# DCC_DCC2_00800000h register map
Vendor: Texas Instruments
Peripheral module from a debugger description file (folder AM275x).
Registers are 32-bit, read-write, reset 0x0 unless marked. A register's access mark holds for its fields unless they carry their own. Offsets are as the file gives them; lines under a group give offsets from that group; [hi:lo] are bit positions; {n}, {i} and the like mark numbered series; 'fields as' and 'values as' point back to an identical list; <NAME> marks a mode.

## dcc2
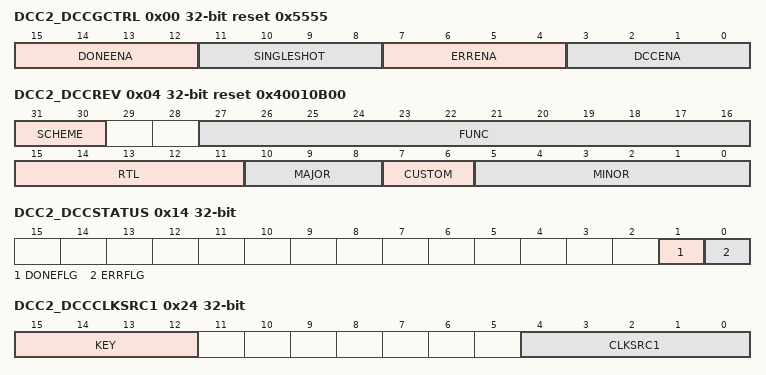
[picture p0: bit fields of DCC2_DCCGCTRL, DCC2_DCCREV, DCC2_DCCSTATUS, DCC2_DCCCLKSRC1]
0x00 DCC2_DCCGCTRL reset 0x5555 — Starts / stops the counters. Clears the error signal.
  [15:12] DONEENA — The DONEENA bit enables/disables the done interrupt signal, but has no effect on the done status flag in DCCSTAT register. User, privilege, and debug mode (read): 0101 = the done signal is disabled others = the done signal is enabled Privilege and debug mode (write): 0101 = disable done signal generation others = enable done signal generation
  [11:8] SINGLESHOT — The SINGLESHOT bit enables/disables repetitive operation of the DCC. User, privilege, and debug mode (read): 1010 = stop counting when counter0 and valid0 both reach zero 1011 = stop counting when counter1 reaches zero others = continuously repeat (until error) Privilege and debug mode (write): 1010 = stop counting when counter0 and valid0 both reach zero 1011 = stop counting when counter1 reaches zero others = continuously repeat (until error)
  [7:4] ERRENA — The ERRENA bit enables/disables the error signal. User, privilege, and debug mode (read): 0101 = the error signal is disabled others = the error signal is enabled Privilege and debug mode (write): 0101 = disable error signal generation others = enable error signal generation
  [3:0] DCCENA — The DCCENA bit starts and stops the operation of the dcc. User, privilege, and debug mode (read): 0101 = counters are stopped others = counters are running Privilege and debug mode (write): 0101 = stop counters and error-checking others = load the counters with their seed values and begin counting
0x04 DCC2_DCCREV ro reset 0x40010B00 — Specifies the module version.
  [31:30] SCHEME — User, privilege, and debug mode (read): Returns 01. Privilege and debug mode (write): Writes have no effect.
  [27:16] FUNC — Reflects software-compatability. If there is no level of software compatability, a unique func number is assigned; for compatible modules, the same number is maintained. User, privilege, and debug mode (read): 0x0 Privilege and debug mode (write): Writes have no effect.
  [15:11] RTL — Incremented for releases due to spec changes or post-release design changes. Reset to 0 when either MAJOR or MINOR is incremented. User, privilege, and debug mode (read): 0x1 Privilege and debug mode (write): Writes have no effect.
  [10:8] MAJOR — Represents major changes to the module (e.g. entirely new features are added/changed). The major revision number for this module. User, privilege, and debug mode (read): 0x2 Privilege and debug mode (write): Writes have no effect.
  [7:6] CUSTOM — Indicates a special version of the module. May not be supported by standard software. User, privilege, and debug mode (read): 0x0 Privilege and debug mode (write): Writes have no effect.
  [5:0] MINOR — Represents minor changes to the module (e.g. enhancements to existing features). The minor revision number for this module. User, privilege, and debug mode (read): 0x4 Privilege and debug mode (write): Writes have no effect.
0x08 DCC2_DCCCNTSEED0 — Seed value for the counter attached to clock source 0
  [19:0] COUNTSEED0 — This field contains the seed value that gets loaded into counter 0 (clock source 0). User, privilege, and debug mode (read): Returns the current seed value for counter 0. Privilege and debug mode (write): Sets the current seed value for counter 0. NOTE - Operating the DCC with 0 in the COUNTSEED0 register will result in undefined operation. NOTE: Operating the DCC with 0 in the COUNTSEED0 register will result in undefined operation.
0x0C DCC2_DCCVALIDSEED0 — Seed value for the timeout counter attached to clock source 0.
  [15:0] VALIDSEED0 — This field contains the seed value that gets loaded into the valid duration counter for clock source 0. User, privilege, and debug mode (read): Returns the current seed value for VALID0. Privilege and debug mode (write): Sets the current seed value for VALID0. NOTE - Operating the DCC with 0 in the VALIDSEED0 register will result in undefined operation. VALID0 defines a window in which COUNT1 expires. This window is meant to be at least four cycles wide. Do not program a value less than 4 into the VALID0 register. NOTE: Operating the DCC with 0 in the VALIDSEED0 register will result in undefined operation. VALID0 defines a window in which COUNT1 expires. This window is meant to be at least four cycles wide. Do not program a value less than 4 into the VALID0 register.
0x10 DCC2_DCCCNTSEED1 — Seed value for the counter attached to clock source 1.
  [19:0] COUNTSEED1 — This field contains the seed value that gets loaded into counter 1 (clock source 1). User, privilege, and debug mode (read): Returns the current seed value for counter 1. Privilege and debug mode (write): Sets the current seed value for counter 1. NOTE - Operating the DCC with 0 in the COUNTSEED1 register will result in undefined operation. NOTE: Operating the DCC with 0 in the COUNTSEED1 register will result in undefined operation.
0x14 DCC2_DCCSTATUS access not given — Specifies the status of the DCC Module.
  [1] DONEFLG — Indicates when single-shot mode is complete without error. Writing a 1 to this bit clears the flag. User, privilege, and debug mode (read): 0 = single-shot mode is not done 1 = single-shot mode is done Privilege and debug mode (write): 0 = no effect 1 = clear the done flag (access R/W1TC)
  [0] ERRFLG — Indicates whether or not an error has occured. Writing a 1 to this bit clears the flag. User, privilege, and debug mode (read): 0 = an error has not occurred 1 = an error has occurred Privilege and debug mode (write): 0 = no effect 1 = clear the error flag (access R/W1TC)
0x18 DCC2_DCCCNT0 ro — Value of the counter attached to clock source 0.
  [19:0] COUNT0 — This field contains the current value of counter 0. User, privilege, and debug mode (read): Returns the current value for counter 0. Privilege and debug mode (write): Writes have no effect. NOTE - Reads of the counter value may not be exact since the read operation is synchronized to the vbus clock. NOTE: Reads of the counter value may not be exact since the read operation is synchronized to the vbus clock.
0x1C DCC2_DCCVALID0 ro — Value of the valid counter attached to clock source 0.
  [15:0] VALID0 — This field contains the current value of valid counter 0. User, privilege, and debug mode (read): Returns the current value for valid counter 0. Privilege and debug mode (write): writes have no effect. NOTE - Reads of the counter value may not be exact since the read operation is synchronized to the vbus clock. NOTE: Reads of the counter value may not be exact since the read operation is synchronized to the vbus clock.
0x20 DCC2_DCCCNT1 ro — Value of the counter attached to clock source 1.
  [19:0] COUNT1 — This field contains the current value of counter 1. User, privilege, and debug mode (read): Returns the current value for counter 1. Privilege and debug mode (write): writes have no effect. NOTE - Reads of the counter value may not be exact since the read operation is synchronized to the vbus clock. NOTE: Reads of the counter value may not be exact since the read operation is synchronized to the vbus clock.
0x24 DCC2_DCCCLKSRC1 — Selects the clock source for counter 1.
  [15:12] KEY — This field enables or disables clock source selection for counter 1. User, privilege, and debug mode (read): Returns the current value of the key. Privilege and debug mode (write): Sets the key value. Key values: 1010: The CLKSRC field selects the clock source for counter 1. others: Clock source selection is disabled. The secondary oscillator (clock source 1) is selected for counter 1.
  [4:0] CLKSRC1 — This field specifies the clock source for counter 1, when the KEY field enables this feature.User, privilege, and debug mode (read):Returns the current value of CLKSRC.Privilege and debug mode (write):Sets the value of CLKSRC.NOTE: DCC does not generate an error when the clock source is VCLK and VCLK is not present. Note: newer versions of DCC only provide one encoding for VCLK selection (MS encodings are tied off) 0000 Clk source 0 is selected for COUNT10001 Clk source 1 is selected for COUNT10010 Clk source 2 is selected for COUNT10011 Clk source 3 is selected for COUNT10100 Clk source 4 is selected for COUNT10101 Clk source 5 is selected for COUNT10110 Clk source 6 is selected for COUNT10111 Clk source 7 is selected for COUNT11000- VCLK is selected for COUNT11111
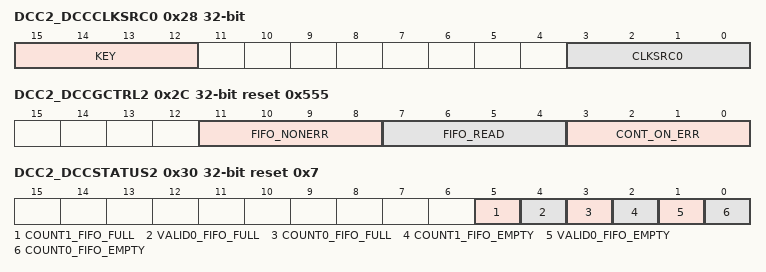
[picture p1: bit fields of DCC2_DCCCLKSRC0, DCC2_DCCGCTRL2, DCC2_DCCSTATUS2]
0x28 DCC2_DCCCLKSRC0 — Selects the clock source for counter 0.
  [15:12] KEY — This field enables or disables clock source selection for counter 0. User, privilege, and debug mode (read): Returns the current value of the key. Privilege and debug mode (write): Sets the key value. Key values: 1010: The CLKSRC field selects the clock source for counter 0. others: Clock source selection is disabled. The external oscillator (XTAL) is selected for counter 0.
  [3:0] CLKSRC0 — This field specifies the clock source for counter 0.User, privilege, and debug mode (read):Returns the current value of CLKSRC0.Privilege and debug mode (write):Sets the value of CLKSRC0.NOTE: DCC does not generate an error when the clock source is VCLK and VCLK is not present. Note: newer versions of DCC only provide one encoding for VCLK selection (MS encodings are tied off)NOTE: DCC does not generate an error when the clock source is VCLK and VCLK is not present. Note: newer versions of DCC only provide one encoding for VCLK selection (MS encodings are tied off) 0000 Clock0[0] is selected as source for COUNT00001 Clock0[1] is selected as source for COUNT00010 Clock0[2] is selected as source for COUNT0Other VCLK is selected as source for COUNT0Values
0x2C DCC2_DCCGCTRL2 reset 0x555 — Allows configuring different modes of operation for DCC.
  [11:8] FIFO_NONERR — Enables/disables FIFO writes without the error event on completion of comparison window. User, privilege, and debug mode (read): Returns the current field value. Privilege and debug mode (write): Sets the value of field value. Source values: 0101: Counter values are captured to non-full FIFO only upon Error event. Others: Write counter values to non-full FIFO upon completion of comparison window regardless of error or not. Note: this setting is applicable only in Continuous mode; in single shot mode FIFO captures counts only on Error. Note: The user should write 1010 to these enable fields to enable each feature to avoid single soft errors.
  [7:4] FIFO_READ — Enables the counter read registers reflect FIFO output instead of the live counter value. User, privilege, and debug mode (read): Returns the current field value. Privilege and debug mode (write): Sets the value of field value. Source values: 0101: Counter value is read directly. Others: Counters FIFO output is read. Note: The user should write 1010 to these enable fields to enable each feature to avoid single soft errors.
  [3:0] CONT_ON_ERR — Continues to next window of comparison despite the error condition. User, privilege, and debug mode (read): Returns the current field value. Privilege and debug mode (write): Sets the value of field value. Enable values: 0101: Comparison and counter reload is stopped from advancing if error is detected. Others: Counters get reloaded with seed and continue counting despite the error condition. Note: The user should write 1010 to these enable fields to enable each feature to avoid single soft errors.
0x30 DCC2_DCCSTATUS2 ro reset 0x7 — Specifies the status of the DCC FIFOs.
  [5] COUNT1_FIFO_FULL — Count1 FIFO Full. Indicates whether Count1 FIFO is full. User, privilege, and debug mode (read): 0: Count1 FIFO is not full 1: Count1 FIFO is full. Privilege and debug mode (write): Writes have no effect.
  [4] VALID0_FIFO_FULL — Valid0 FIFO Full. Indicates whether Valid0 FIFO is full. User, privilege, and debug mode (read): 0: Valid0 FIFO is not full 1: Valid0 FIFO is full. Privilege and debug mode (write): Writes have no effect.
  [3] COUNT0_FIFO_FULL — Count0 FIFO Full. Indicates whether Count0 FIFO is full. User, privilege, and debug mode (read): 0: Count0 FIFO is not full 1: Count0 FIFO is full. Privilege and debug mode (write): Writes have no effect.
  [2] COUNT1_FIFO_EMPTY — Count1 FIFO Empty. Indicates whether Count1 FIFO is empty. User, privilege, and debug mode (read): 0: Count1 FIFO is not empty 1: Count1 FIFO is empty. Privilege and debug mode (write): Writes have no effect.
  [1] VALID0_FIFO_EMPTY — Valid0 FIFO Empty. Indicates whether Valid0 FIFO is empty. User, privilege, and debug mode (read): 0: Valid0 FIFO is not empty 1: Valid0 FIFO is empty. Privilege and debug mode (write): Writes have no effect.
  [0] COUNT0_FIFO_EMPTY — Count0 FIFO Empty. Indicates whether Count0 FIFO is empty. User, privilege, and debug mode (read): 0: Count0 FIFO is not empty 1: Count0 FIFO is empty. Privilege and debug mode (write): Writes have no effect.
0x34 DCC2_DCCERRCNT — Counts number of errors since last clear.
  [9:0] ERRCNT — Counts the number of errors after the last write to this register or reset. If reached terminal count the count freezes. User needs to clear it.
